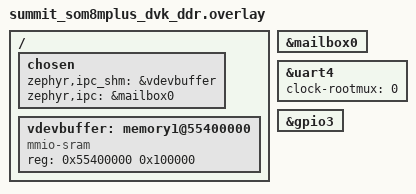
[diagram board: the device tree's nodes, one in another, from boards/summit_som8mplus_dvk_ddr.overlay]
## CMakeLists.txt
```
#
# Copyright (c) 2022 Laird Connectivity
#
# SPDX-License-Identifier: Apache-2.0
#

cmake_minimum_required(VERSION 3.20.0)

# Prepend the additional boards directory but still allow the original Zephyr
# boards directory to be used with lower priority
list(PREPEND BOARD_ROOT ${CMAKE_CURRENT_LIST_DIR}/../../)

set(rpmsg_lite_dir ${CMAKE_CURRENT_SOURCE_DIR}/../../modules/rpmsg_lite)

find_package(Zephyr REQUIRED HINTS $ENV{ZEPHYR_BASE})
project("RPMsg-Lite String Echo Example")

target_sources(app PRIVATE
	${rpmsg_lite_dir}/lib/common/llist.c
	${rpmsg_lite_dir}/lib/rpmsg_lite/rpmsg_lite.c
	${rpmsg_lite_dir}/lib/rpmsg_lite/rpmsg_ns.c
	${rpmsg_lite_dir}/lib/rpmsg_lite/rpmsg_queue.c
	${rpmsg_lite_dir}/lib/virtio/virtqueue.c
	${CMAKE_SOURCE_DIR}/src/main.c
	${CMAKE_SOURCE_DIR}/src/rsc_table.c
	${CMAKE_SOURCE_DIR}/src/rpmsg_env_zephyr.c
	${CMAKE_SOURCE_DIR}/src/rpmsg_platform.c
)

include_directories(
	${rpmsg_lite_dir}/lib/include
	${rpmsg_lite_dir}/lib/include/environment/zephyr
	${rpmsg_lite_dir}/lib/include/platform/imx8mp_m7
	${CMAKE_SOURCE_DIR}/include
)
```

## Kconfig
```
#
# Copyright (c) 2022 Laird Connectivity
#
# SPDX-License-Identifier: Apache-2.0
#

menu "RPMsg-Lite String Echo Example"

config RPMSG_LITE_RESOURCE_TABLE
	bool "coprocessor resource table"
	help
	  Add the resource table in the generated binary. This table is
	  compatible with linux remote proc framework and RPMsg-Lite library.

config RPMSG_LITE_IPC_DEV_NAME
	string "RPMsg-Lite IPC device name"
	default "MAILBOX_0"

config RPMSG_LITE_APP_STACKSIZE
	int "Application thread stack size"
	default 4096

endmenu

module = MAIN
module-str = MAIN
source "subsys/logging/Kconfig.template.log_config"

source "Kconfig.zephyr"
```

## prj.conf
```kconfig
CONFIG_RPMSG_LITE_RESOURCE_TABLE=y
CONFIG_IPM=y
CONFIG_HEAP_MEM_POOL_SIZE=4096
CONFIG_IPM_IMX_REV2=y
CONFIG_IPM_IMX_MAX_DATA_SIZE_4=y
CONFIG_HAVE_CUSTOM_LINKER_SCRIPT=y
CONFIG_CUSTOM_LINKER_SCRIPT="linker.ld"
CONFIG_LOG=y
CONFIG_MAIN_LOG_LEVEL_INF=y
```

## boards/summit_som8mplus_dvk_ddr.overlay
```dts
/*
 * Copyright (c) 2022, Laird Connectivity
 *
 * SPDX-License-Identifier: Apache-2.0
 */

/ {
	chosen {
		/*
		 * shared memory reserved for the inter-processor communication
		 */
		zephyr,ipc_shm = &vdevbuffer;
		zephyr,ipc = &mailbox0;
	};

	vdevbuffer: memory1@55400000 {
		compatible = "mmio-sram";
		reg = <0x55400000 0x100000>;
	};
};

&mailbox0 {
	status = "okay";
};

&uart4 {
	clock-rootmux = <0>;
};

&gpio3 {
	status = "okay";
};
```

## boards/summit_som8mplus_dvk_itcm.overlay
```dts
/*
 * Copyright (c) 2022, Laird Connectivity
 *
 * SPDX-License-Identifier: Apache-2.0
 */

/ {
	chosen {
		/*
		 * shared memory reserved for the inter-processor communication
		 */
		zephyr,ipc_shm = &vdevbuffer;
		zephyr,ipc = &mub;
	};

	vdevbuffer: memory1@55400000 {
		compatible = "mmio-sram";
		reg = <0x55400000 0x100000>;
	};
};

&mub {
	status ="okay";
};
```

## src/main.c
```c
/*
 * Copyright (c) 2022 Laird Connectivity
 *
 * SPDX-License-Identifier: Apache-2.0
 */

#include <zephyr.h>
#include <stdint.h>
#include <string.h>

#include "rpmsg_lite.h"
#include "rpmsg_queue.h"
#include "rpmsg_ns.h"
#include "rsc_table.h"
#include "rpmsg_lite_str_echo.h"

#include <logging/log.h>

#include "fsl_rdc.h"

#define M7_DOMAIN_ID (1U)
#define A53_DOMAIN_ID (0U)

LOG_MODULE_REGISTER(main, LOG_LEVEL_INF);

/* Globals */
/* Each RPMSG buffer can carry less than 512 payload */
static char app_buf[512];
static struct k_thread app_thread;
K_THREAD_STACK_DEFINE(app_stack, CONFIG_RPMSG_LITE_APP_STACKSIZE);

void rdc_configure_peripheral_access(void)
{
	rdc_domain_assignment_t assignment = { 0 };
	rdc_periph_access_config_t periph_config;

	assignment.domainId = M7_DOMAIN_ID;

	/* Only configure the RDC if the RDC peripheral write access is allowed. */
	if ((0x1U & RDC_GetPeriphAccessPolicy(RDC, kRDC_Periph_RDC, assignment.domainId)) != 0U) {
		RDC_GetDefaultPeriphAccessConfig(&periph_config);

		/* Give the A53 domain (domain0) access to the I2C3 and SAI3 peripherals. */
		periph_config.policy = RDC_ACCESS_POLICY(A53_DOMAIN_ID, kRDC_ReadWrite);
		periph_config.periph = kRDC_Periph_I2C3;
		RDC_SetPeriphAccessConfig(RDC, &periph_config);
		periph_config.periph = kRDC_Periph_SAI3;
		RDC_SetPeriphAccessConfig(RDC, &periph_config);
	}
}

void app_task(void *p1, void *p2, void *p3)
{
	volatile uint32_t remote_addr;
	struct rpmsg_lite_endpoint *volatile my_ept;
	volatile rpmsg_queue_handle my_queue;
	struct rpmsg_lite_instance *volatile my_rpmsg;
	void *rx_buf;
	uint32_t len;
	int32_t result;
	void *tx_buf;
	uint32_t size;

	ARG_UNUSED(p1);
	ARG_UNUSED(p2);
	ARG_UNUSED(p3);

	copy_resource_table();

	/* Print the initial banner */
	LOG_INF("RPMSG String Echo Zephyr RTOS API Demo");

	my_rpmsg = rpmsg_lite_remote_init((void *)RPMSG_LITE_SHMEM_BASE, RPMSG_LITE_LINK_ID,
					  RL_NO_FLAGS);
	__ASSERT(my_rpmsg != RL_NULL, "Unable to init rpmsg lite");

	while (0 == rpmsg_lite_is_link_up(my_rpmsg))
		;

	my_queue = rpmsg_queue_create(my_rpmsg);
	my_ept = rpmsg_lite_create_ept(my_rpmsg, LOCAL_EPT_ADDR, rpmsg_queue_rx_cb, my_queue);
	(void)rpmsg_ns_announce(my_rpmsg, my_ept, RPMSG_LITE_NS_ANNOUNCE_STRING, RL_NS_CREATE);

	LOG_INF("Nameservice sent, ready for incoming messages...");

	for (;;) {
		/* Get RPMsg rx buffer with message */
		result = rpmsg_queue_recv_nocopy(my_rpmsg, my_queue, (uint32_t *)&remote_addr,
						 (char **)&rx_buf, &len, RL_BLOCK);
		if (result != 0) {
			__ASSERT(false, "Failed to queue the message");
		}

		/* Copy string from RPMsg rx buffer */
		__ASSERT(len < sizeof(app_buf), "rx message is too big");
		memcpy(app_buf, rx_buf, len);
		/* End string by '\0' */
		app_buf[len] = 0;

		if ((len == 2) && (app_buf[0] == 0xd) && (app_buf[1] == 0xa)) {
			LOG_INF("Get New Line From Master Side");
		} else {
			LOG_INF("Get Message From Master Side : \"%s\" [len : %d]", log_strdup(app_buf), len);
		}

		/* Get tx buffer from RPMsg */
		tx_buf = rpmsg_lite_alloc_tx_buffer(my_rpmsg, &size, RL_BLOCK);
		__ASSERT(tx_buf, "Failed to read tx buffer");
		/* Copy string to RPMsg tx buffer */
		memcpy(tx_buf, app_buf, len);
		/* Echo back received message with nocopy send */
		result = rpmsg_lite_send_nocopy(my_rpmsg, my_ept, remote_addr, tx_buf, len);
		if (result != 0) {
			__ASSERT(false, "Failed to send message");
		}
		/* Release held RPMsg rx buffer */
		result = rpmsg_queue_nocopy_free(my_rpmsg, rx_buf);
		if (result != 0) {
			__ASSERT(false, "Failed to free the rx buffer");
		}
	}
}

void main(void)
{
	rdc_configure_peripheral_access();

	k_thread_create(&app_thread, app_stack, CONFIG_RPMSG_LITE_APP_STACKSIZE, app_task, NULL,
			NULL, NULL, -1, K_USER, K_MSEC(0));
}
```

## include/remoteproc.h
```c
/*
 * Copyright (c) 2022 Laird Connectivity
 *
 * SPDX-License-Identifier: Apache-2.0
 */

#ifndef REMOTEPROC_H
#define REMOTEPROC_H

#include <stdint.h>

#if defined __cplusplus
extern "C" {
#endif

#define RSC_NOTIFY_ID_ANY 0xFFFFFFFFUL

#define RPROC_MAX_NAME_LEN 32

/* IAR ARM build tools */
#if defined(__ICCARM__)

#ifndef METAL_PACKED_BEGIN
#define METAL_PACKED_BEGIN __packed
#endif

#ifndef METAL_PACKED_END
#define METAL_PACKED_END
#endif

/* GNUC */
#elif defined(__GNUC__)

#ifndef METAL_PACKED_BEGIN
#define METAL_PACKED_BEGIN
#endif

#ifndef METAL_PACKED_END
#define METAL_PACKED_END __attribute__((__packed__))
#endif

/* ARMCC */
#elif defined(__CC_ARM) || defined(__ARMCC_VERSION)

#ifndef METAL_PACKED_BEGIN
#define METAL_PACKED_BEGIN _Pragma("pack(1U)")
#endif

#ifndef METAL_PACKED_END
#define METAL_PACKED_END _Pragma("pack()")
#endif

#else
/* There is no default definition here to avoid wrong structures packing in case of not supported compiler */
#error Please implement the structure packing macros for your compiler here!
#endif

/**
 * struct resource_table - firmware resource table header
 * @ver: version number
 * @num: number of resource entries
 * @reserved: reserved (must be zero)
 * @offset: array of offsets pointing at the various resource entries
 *
 * A resource table is essentially a list of system resources required
 * by the remote remoteproc. It may also include configuration entries.
 * If needed, the remote remoteproc firmware should contain this table
 * as a dedicated ".resource_table" ELF section.
 *
 * Some resources entries are mere announcements, where the host is informed
 * of specific remoteproc configuration. Other entries require the host to
 * do something (e.g. allocate a system resource). Sometimes a negotiation
 * is expected, where the firmware requests a resource, and once allocated,
 * the host should provide back its details (e.g. address of an allocated
 * memory region).
 *
 * The header of the resource table, as expressed by this structure,
 * contains a version number (should we need to change this format in the
 * future), the number of available resource entries, and their offsets
 * in the table.
 *
 * Immediately following this header are the resource entries themselves,
 * each of which begins with a resource entry header (as described below).
 */
METAL_PACKED_BEGIN
struct resource_table
{
    uint32_t ver;
    uint32_t num;
    uint32_t reserved[2];
    uint32_t offset[0];
} METAL_PACKED_END;

/**
 * struct fw_rsc_hdr - firmware resource entry header
 * @type: resource type
 * @data: resource data
 *
 * Every resource entry begins with a 'struct fw_rsc_hdr' header providing
 * its @type. The content of the entry itself will immediately follow
 * this header, and it should be parsed according to the resource type.
 */
METAL_PACKED_BEGIN
struct fw_rsc_hdr
{
    uint32_t type;
    uint8_t data[0];
} METAL_PACKED_END;

/**
 * enum fw_resource_type - types of resource entries
 *
 * @RSC_CARVEOUT:   request for allocation of a physically contiguous
 *          memory region.
 * @RSC_DEVMEM:     request to iommu_map a memory-based peripheral.
 * @RSC_TRACE:      announces the availability of a trace buffer into which
 *          the remote remoteproc will be writing logs.
 * @RSC_VDEV:       declare support for a virtio device, and serve as its
 *          virtio header.
 * @RSC_VENDOR_START: start of the vendor specific resource types range
 * @RSC_VENDOR_END  : end of the vendor specific resource types range
 * @RSC_LAST:       just keep this one at the end
 *
 * For more details regarding a specific resource type, please see its
 * dedicated structure below.
 *
 * Please note that these values are used as indices to the rproc_handle_rsc
 * lookup table, so please keep them sane. Moreover, @RSC_LAST is used to
 * check the validity of an index before the lookup table is accessed, so
 * please update it as needed.
 */
enum fw_resource_type
{
    RSC_CARVEOUT     = 0,
    RSC_DEVMEM       = 1,
    RSC_TRACE        = 2,
    RSC_VDEV         = 3,
    RSC_LAST         = 4,
    RSC_VENDOR_START = 128,
    RSC_VENDOR_END   = 512,
};

#define FW_RSC_U64_ADDR_ANY 0xFFFFFFFFFFFFFFFFUL
#define FW_RSC_U32_ADDR_ANY 0xFFFFFFFFUL

/**
 * struct fw_rsc_carveout - physically contiguous memory request
 * @da: device address
 * @pa: physical address
 * @len: length (in bytes)
 * @flags: iommu protection flags
 * @reserved: reserved (must be zero)
 * @name: human-readable name of the requested memory region
 *
 * This resource entry requests the host to allocate a physically contiguous
 * memory region.
 *
 * These request entries should precede other firmware resource entries,
 * as other entries might request placing other data objects inside
 * these memory regions (e.g. data/code segments, trace resource entries, ...).
 *
 * Allocating memory this way helps utilizing the reserved physical memory
 * (e.g. CMA) more efficiently, and also minimizes the number of TLB entries
 * needed to map it (in case @rproc is using an IOMMU). Reducing the TLB
 * pressure is important; it may have a substantial impact on performance.
 *
 * If the firmware is compiled with static addresses, then @da should specify
 * the expected device address of this memory region. If @da is set to
 * FW_RSC_ADDR_ANY, then the host will dynamically allocate it, and then
 * overwrite @da with the dynamically allocated address.
 *
 * We will always use @da to negotiate the device addresses, even if it
 * isn't using an iommu. In that case, though, it will obviously contain
 * physical addresses.
 *
 * Some remote remoteprocs needs to know the allocated physical address
 * even if they do use an iommu. This is needed, e.g., if they control
 * hardware accelerators which access the physical memory directly (this
 * is the case with OMAP4 for instance). In that case, the host will
 * overwrite @pa with the dynamically allocated physical address.
 * Generally we don't want to expose physical addresses if we don't have to
 * (remote remoteprocs are generally _not_ trusted), so we might want to
 * change this to happen _only_ when explicitly required by the hardware.
 *
 * @flags is used to provide IOMMU protection flags, and @name should
 * (optionally) contain a human readable name of this carveout region
 * (mainly for debugging purposes).
 */
METAL_PACKED_BEGIN
struct fw_rsc_carveout
{
    uint32_t type;
    uint32_t da;
    uint32_t pa;
    uint32_t len;
    uint32_t flags;
    uint32_t reserved;
    uint8_t name[RPROC_MAX_NAME_LEN];
} METAL_PACKED_END;

/**
 * struct fw_rsc_devmem - iommu mapping request
 * @da: device address
 * @pa: physical address
 * @len: length (in bytes)
 * @flags: iommu protection flags
 * @reserved: reserved (must be zero)
 * @name: human-readable name of the requested region to be mapped
 *
 * This resource entry requests the host to iommu map a physically contiguous
 * memory region. This is needed in case the remote remoteproc requires
 * access to certain memory-based peripherals; _never_ use it to access
 * regular memory.
 *
 * This is obviously only needed if the remote remoteproc is accessing memory
 * via an iommu.
 *
 * @da should specify the required device address, @pa should specify
 * the physical address we want to map, @len should specify the size of
 * the mapping and @flags is the IOMMU protection flags. As always, @name may
 * (optionally) contain a human readable name of this mapping (mainly for
 * debugging purposes).
 *
 * Note: at this point we just "trust" those devmem entries to contain valid
 * physical addresses, but this isn't safe and will be changed: eventually we
 * want remoteproc implementations to provide us ranges of physical addresses
 * the firmware is allowed to request, and not allow firmwares to request
 * access to physical addresses that are outside those ranges.
 */
METAL_PACKED_BEGIN
struct fw_rsc_devmem
{
    uint32_t type;
    uint32_t da;
    uint32_t pa;
    uint32_t len;
    uint32_t flags;
    uint32_t reserved;
    uint8_t name[RPROC_MAX_NAME_LEN];
} METAL_PACKED_END;

/**
 * struct fw_rsc_trace - trace buffer declaration
 * @da: device address
 * @len: length (in bytes)
 * @reserved: reserved (must be zero)
 * @name: human-readable name of the trace buffer
 *
 * This resource entry provides the host information about a trace buffer
 * into which the remote remoteproc will write log messages.
 *
 * @da specifies the device address of the buffer, @len specifies
 * its size, and @name may contain a human readable name of the trace buffer.
 *
 * After booting the remote remoteproc, the trace buffers are exposed to the
 * user via debugfs entries (called trace0, trace1, etc..).
 */
METAL_PACKED_BEGIN
struct fw_rsc_trace
{
    uint32_t type;
    uint32_t da;
    uint32_t len;
    uint32_t reserved;
    uint8_t name[RPROC_MAX_NAME_LEN];
} METAL_PACKED_END;

/**
 * struct fw_rsc_vdev_vring - vring descriptor entry
 * @da: device address
 * @align: the alignment between the consumer and producer parts of the vring
 * @num: num of buffers supported by this vring (must be power of two)
 * @notifyid is a unique rproc-wide notify index for this vring. This notify
 * index is used when kicking a remote remoteproc, to let it know that this
 * vring is triggered.
 * @reserved: reserved (must be zero)
 *
 * This descriptor is not a resource entry by itself; it is part of the
 * vdev resource type (see below).
 *
 * Note that @da should either contain the device address where
 * the remote remoteproc is expecting the vring, or indicate that
 * dynamically allocation of the vring's device address is supported.
 */
METAL_PACKED_BEGIN
struct fw_rsc_vdev_vring
{
    uint32_t da;
    uint32_t align;
    uint32_t num;
    uint32_t notifyid;
    uint32_t reserved;
} METAL_PACKED_END;

/**
 * struct fw_rsc_vdev - virtio device header
 * @id: virtio device id (as in virtio_ids.h)
 * @notifyid is a unique rproc-wide notify index for this vdev. This notify
 * index is used when kicking a remote remoteproc, to let it know that the
 * status/features of this vdev have changes.
 * @dfeatures specifies the virtio device features supported by the firmware
 * @gfeatures is a place holder used by the host to write back the
 * negotiated features that are supported by both sides.
 * @config_len is the size of the virtio config space of this vdev. The config
 * space lies in the resource table immediate after this vdev header.
 * @status is a place holder where the host will indicate its virtio progress.
 * @num_of_vrings indicates how many vrings are described in this vdev header
 * @reserved: reserved (must be zero)
 * @vring is an array of @num_of_vrings entries of 'struct fw_rsc_vdev_vring'.
 *
 * This resource is a virtio device header: it provides information about
 * the vdev, and is then used by the host and its peer remote remoteprocs
 * to negotiate and share certain virtio properties.
 *
 * By providing this resource entry, the firmware essentially asks remoteproc
 * to statically allocate a vdev upon registration of the rproc (dynamic vdev
 * allocation is not yet supported).
 *
 * Note: unlike virtualization systems, the term 'host' here means
 * the Linux side which is running remoteproc to control the remote
 * remoteprocs. We use the name 'gfeatures' to comply with virtio's terms,
 * though there isn't really any virtualized guest OS here: it's the host
 * which is responsible for negotiating the final features.
 * Yeah, it's a bit confusing.
 *
 * Note: immediately following this structure is the virtio config space for
 * this vdev (which is specific to the vdev; for more info, read the virtio
 * spec). the size of the config space is specified by @config_len.
 */
METAL_PACKED_BEGIN
struct fw_rsc_vdev
{
    uint32_t type;
    uint32_t id;
    uint32_t notifyid;
    uint32_t dfeatures;
    uint32_t gfeatures;
    uint32_t config_len;
    uint8_t status;
    uint8_t num_of_vrings;
    uint8_t reserved[2];
    struct fw_rsc_vdev_vring vring[0];
} METAL_PACKED_END;

/**
 * struct fw_rsc_vendor - remote processor vendor specific resource
 * @len: length of the resource
 *
 * This resource entry tells the host the vendor specific resource
 * required by the remote.
 *
 * These request entries should precede other shared resource entries
 * such as vdevs, vrings.
 */
METAL_PACKED_BEGIN
struct fw_rsc_vendor
{
    uint32_t type;
    uint32_t len;
} METAL_PACKED_END;

#if defined __cplusplus
}
#endif

#endif /* REMOTEPROC_H_ */
```

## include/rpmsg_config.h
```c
/*
 * Copyright (c) 2022 Laird Connectivity
 *
 * SPDX-License-Identifier: Apache-2.0
 */

#ifndef RPMSG_CONFIG_H_
#define RPMSG_CONFIG_H_

/*!
 * @addtogroup config
 * @{
 * @file
 */

//! @name Configuration options
//@{

//! @def RL_MS_PER_INTERVAL
//!
//! Delay in milliseconds used in non-blocking API functions for polling.
//! The default value is 1.
#define RL_MS_PER_INTERVAL (1)

//! @def RL_BUFFER_PAYLOAD_SIZE
//!
//! Size of the buffer payload, it must be equal to (240, 496, 1008, ...)
//! [2^n - 16]. Ensure the same value is defined on both sides of rpmsg
//! communication. The default value is 496U.
#define RL_BUFFER_PAYLOAD_SIZE (496U)

//! @def RL_BUFFER_COUNT
//!
//! Number of the buffers, it must be power of two (2, 4, ...).
//! The default value is 2U.
//! Note this value defines the buffer count for one direction of the rpmsg
//! communication only, i.e. if the default value of 2 is used
//! in rpmsg_config.h files for the master and the remote side, 4 buffers
//! in total are created in the shared memory.
#define RL_BUFFER_COUNT (256U)

//! @def RL_API_HAS_ZEROCOPY
//!
//! Zero-copy API functions enabled/disabled.
//! The default value is 1 (enabled).
#define RL_API_HAS_ZEROCOPY (1)

//! @def RL_USE_STATIC_API
//!
//! Static API functions (no dynamic allocation) enabled/disabled.
//! The default value is 0 (static API disabled).
#define RL_USE_STATIC_API (0)

//! @def RL_CLEAR_USED_BUFFERS
//!
//! Clearing used buffers before returning back to the pool of free buffers
//! enabled/disabled.
//! The default value is 0 (disabled).
#define RL_CLEAR_USED_BUFFERS (0)

//! @def RL_USE_MCMGR_IPC_ISR_HANDLER
//!
//! When enabled IPC interrupts are managed by the Multicore Manager (IPC
//! interrupts router), when disabled RPMsg-Lite manages IPC interrupts
//! by itself.
//! The default value is 0 (no MCMGR IPC ISR handler used).
#define RL_USE_MCMGR_IPC_ISR_HANDLER (0)

//! @def RL_USE_ENVIRONMENT_CONTEXT
//!
//! When enabled the environment layer uses its own context.
//! Added for QNX port mainly, but can be used if required.
//! The default value is 0 (no context, saves some RAM).
#define RL_USE_ENVIRONMENT_CONTEXT (0)

//! @def RL_DEBUG_CHECK_BUFFERS
//!
//! Do not use in RPMsg-Lite to Linux configuration
#define RL_DEBUG_CHECK_BUFFERS (0)
//@}

typedef struct {
	uint32_t src;
	void *data;
	uint32_t len;
} rpmsg_queue_rx_cb_data_t;

#endif /* RPMSG_CONFIG_H_ */
```

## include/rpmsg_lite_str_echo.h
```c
/*
 * Copyright (c) 2022 Laird Connectivity
 *
 * SPDX-License-Identifier: Apache-2.0
 */

#ifndef RPMSG_LITE_STR_ECHO_H
#define RPMSG_LITE_STR_ECHO_H

/*******************************************************************************
 * Definitions
 ******************************************************************************/

/* Shared memory base for RPMsg communication. */
#define VDEV0_VRING_BASE (0x55000000U)
#define RESOURCE_TABLE_OFFSET (0xFF000)

#define RPMSG_LITE_SHMEM_BASE (VDEV0_VRING_BASE)
#define RPMSG_LITE_LINK_ID (RL_PLATFORM_IMX8MP_M7_USER_LINK_ID)
#define RPMSG_LITE_NS_ANNOUNCE_STRING "rpmsg-virtual-tty-channel-1"
#define APP_TASK_STACK_SIZE (256)
#ifndef LOCAL_EPT_ADDR
#define LOCAL_EPT_ADDR (30)
#endif

#endif // RPMSG_LITE_STR_ECHO_H
```

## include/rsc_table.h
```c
/*
 * Copyright (c) 2022 Laird Connectivity
 *
 * SPDX-License-Identifier: Apache-2.0
 */

/* This file populates resource table for BM remote
 * for use by the Linux Master */

#ifndef RSC_TABLE_H_
#define RSC_TABLE_H_

#include "rpmsg_lite_str_echo.h"
#include <stddef.h>
#include <remoteproc.h>

#if defined __cplusplus
extern "C" {
#endif

#define NO_RESOURCE_ENTRIES (1)
#define RSC_VDEV_FEATURE_NS (1) /* Support name service announcement */

/* Resource table for the given remote */
METAL_PACKED_BEGIN
struct remote_resource_table {
	uint32_t version;
	uint32_t num;
	uint32_t reserved[2];
	uint32_t offset[NO_RESOURCE_ENTRIES];

	/* rpmsg vdev entry for user app communication */
	struct fw_rsc_vdev user_vdev;
	struct fw_rsc_vdev_vring user_vring0;
	struct fw_rsc_vdev_vring user_vring1;
} METAL_PACKED_END;

/*
 * Copy resource table to shared memory base for early M4 boot case.
 * In M4 early boot case, Linux kernel need to get resource table before file system gets loaded.
 */
void copy_resource_table(void);

#if defined __cplusplus
}
#endif

#endif /* RSC_TABLE_H_ */
```

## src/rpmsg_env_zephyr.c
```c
/*
 * Copyright (c) 2014, Mentor Graphics Corporation
 * Copyright (c) 2015 Xilinx, Inc.
 * Copyright (c) 2016 Freescale Semiconductor, Inc.
 * Copyright 2016-2021 NXP
 * Copyright (c) 2022 Laird Connectivity
 * All rights reserved.
 *
 * Redistribution and use in source and binary forms, with or without
 * modification, are permitted provided that the following conditions are met:
 *
 * 1. Redistributions of source code must retain the above copyright notice,
 *    this list of conditions and the following disclaimer.
 * 2. Redistributions in binary form must reproduce the above copyright notice,
 *    this list of conditions and the following disclaimer in the documentation
 *    and/or other materials provided with the distribution.
 * 3. Neither the name of the copyright holder nor the names of its
 *    contributors may be used to endorse or promote products derived from this
 *    software without specific prior written permission.
 *
 * THIS SOFTWARE IS PROVIDED BY THE COPYRIGHT HOLDERS AND CONTRIBUTORS "AS IS"
 * AND ANY EXPRESS OR IMPLIED WARRANTIES, INCLUDING, BUT NOT LIMITED TO, THE
 * IMPLIED WARRANTIES OF MERCHANTABILITY AND FITNESS FOR A PARTICULAR PURPOSE
 * ARE DISCLAIMED. IN NO EVENT SHALL THE COPYRIGHT HOLDER OR CONTRIBUTORS BE
 * LIABLE FOR ANY DIRECT, INDIRECT, INCIDENTAL, SPECIAL, EXEMPLARY, OR
 * CONSEQUENTIAL DAMAGES (INCLUDING, BUT NOT LIMITED TO, PROCUREMENT OF
 * SUBSTITUTE GOODS OR SERVICES; LOSS OF USE, DATA, OR PROFITS; OR BUSINESS
 * INTERRUPTION) HOWEVER CAUSED AND ON ANY THEORY OF LIABILITY, WHETHER IN
 * CONTRACT, STRICT LIABILITY, OR TORT (INCLUDING NEGLIGENCE OR OTHERWISE)
 * ARISING IN ANY WAY OUT OF THE USE OF THIS SOFTWARE, EVEN IF ADVISED OF THE
 * POSSIBILITY OF SUCH DAMAGE.
 */

/**************************************************************************
 * FILE NAME
 *
 *       rpmsg_env_zephyr.c
 *
 *
 * DESCRIPTION
 *
 *       This file is Zephyr RTOS Implementation of env layer for OpenAMP.
 *
 *
 **************************************************************************/

#include "rpmsg_env.h"
#include <zephyr.h>
#include "rpmsg_platform.h"
#include "virtqueue.h"
#include "rpmsg_compiler.h"

#include <stdlib.h>
#include <string.h>

#if defined(RL_USE_ENVIRONMENT_CONTEXT) && (RL_USE_ENVIRONMENT_CONTEXT == 1)
#error "This RPMsg-Lite port requires RL_USE_ENVIRONMENT_CONTEXT set to 0"
#endif

/* RL_ENV_MAX_MUTEX_COUNT is an arbitrary count greater than 'count'
   if the inital count is 1, this function behaves as a mutex
   if it is greater than 1, it acts as a "resource allocator" with
   the maximum of 'count' resources available.
   Currently, only the first use-case is applicable/applied in RPMsg-Lite.
 */
#define RL_ENV_MAX_MUTEX_COUNT (10)

static int32_t env_init_counter = 0;
static struct k_sem env_sema = { 0 };

/* Max supported ISR counts */
#define ISR_COUNT (32U)
/*!
 * Structure to keep track of registered ISR's.
 */
struct isr_info {
	void *data;
};
static struct isr_info isr_table[ISR_COUNT];

/*!
 * env_in_isr
 *
 * @returns - true, if currently in ISR
 *
 */
static int32_t env_in_isr(void)
{
	return platform_in_isr();
}

/*!
 * env_init
 *
 * Initializes OS/BM environment.
 *
 */
int32_t env_init(void)
{
	int32_t retval;

	/* stop scheduler */
	k_sched_lock();
	/* verify 'env_init_counter' */
	RL_ASSERT(env_init_counter >= 0);
	if (env_init_counter < 0) {
		/* re-enable scheduler */
		k_sched_unlock();
		return -1;
	}
	env_init_counter++;
	/* multiple call of 'env_init' - return ok */
	if (env_init_counter == 1) {
		/* first call */
		k_sem_init(&env_sema, 0, 1);
		(void)memset(isr_table, 0, sizeof(isr_table));
		k_sched_unlock();
		retval = platform_init();
		k_sem_give(&env_sema);

		return retval;
	} else {
		k_sched_unlock();
		/*
		 * Get the semaphore and then return it, this allows for platform_init() to block if
		 * needed and other tasks to wait for the blocking to be done. This is in ENV layer
		 * as this is ENV specific.
		 */
		k_sem_take(&env_sema, K_FOREVER);
		k_sem_give(&env_sema);
		return 0;
	}
}

/*!
 * env_deinit
 *
 * Uninitializes OS/BM environment.
 *
 * @returns - execution status
 */
int32_t env_deinit(void)
{
	int32_t retval;

	/* stop scheduler */
	k_sched_lock();
	/* verify 'env_init_counter' */
	RL_ASSERT(env_init_counter > 0);
	if (env_init_counter <= 0) {
		/* re-enable scheduler */
		k_sched_unlock();
		return -1;
	}

	/* counter on zero - call platform deinit */
	env_init_counter--;
	/* multiple call of 'env_deinit' - return ok */
	if (env_init_counter <= 0) {
		/* last call */
		(void)memset(isr_table, 0, sizeof(isr_table));
		retval = platform_deinit();
		k_sem_reset(&env_sema);
		k_sched_unlock();

		return retval;
	} else {
		k_sched_unlock();
		return 0;
	}
}

/*!
 * env_allocate_memory - implementation
 *
 * @param size
 */
void *env_allocate_memory(uint32_t size)
{
	return (k_malloc(size));
}

/*!
 * env_free_memory - implementation
 *
 * @param ptr
 */
void env_free_memory(void *ptr)
{
	if (ptr != ((void *)0)) {
		k_free(ptr);
	}
}

/*!
 *
 * env_memset - implementation
 *
 * @param ptr
 * @param value
 * @param size
 */
void env_memset(void *ptr, int32_t value, uint32_t size)
{
	(void)memset(ptr, value, size);
}

/*!
 *
 * env_memcpy - implementation
 *
 * @param dst
 * @param src
 * @param len
 */
void env_memcpy(void *dst, void const *src, uint32_t len)
{
	(void)memcpy(dst, src, len);
}

/*!
 *
 * env_strcmp - implementation
 *
 * @param dst
 * @param src
 */

int32_t env_strcmp(const char *dst, const char *src)
{
	return (strcmp(dst, src));
}

/*!
 *
 * env_strncpy - implementation
 *
 * @param dst
 * @param src
 * @param len
 */
void env_strncpy(char *dst, const char *src, uint32_t len)
{
	(void)strncpy(dst, src, len);
}

/*!
 *
 * env_strncmp - implementation
 *
 * @param dst
 * @param src
 * @param len
 */
int32_t env_strncmp(char *dst, const char *src, uint32_t len)
{
	return (strncmp(dst, src, len));
}

/*!
 *
 * env_mb - implementation
 *
 */
void env_mb(void)
{
	MEM_BARRIER();
}

/*!
 * env_rmb - implementation
 */
void env_rmb(void)
{
	MEM_BARRIER();
}

/*!
 * env_wmb - implementation
 */
void env_wmb(void)
{
	MEM_BARRIER();
}

/*!
 * env_map_vatopa - implementation
 *
 * @param address
 */
uint32_t env_map_vatopa(void *address)
{
	return platform_vatopa(address);
}

/*!
 * env_map_patova - implementation
 *
 * @param address
 */
void *env_map_patova(uint32_t address)
{
	return platform_patova(address);
}

/*!
 * env_create_mutex
 *
 * Creates a mutex with the given initial count.
 *
 */
#if defined(RL_USE_STATIC_API) && (RL_USE_STATIC_API == 1)
int32_t env_create_mutex(void **lock, int32_t count, void *context)
#else
int32_t env_create_mutex(void **lock, int32_t count)
#endif
{
	struct k_sem *semaphore_ptr;

	if (count > RL_ENV_MAX_MUTEX_COUNT) {
		return -1;
	}

#if defined(RL_USE_STATIC_API) && (RL_USE_STATIC_API == 1)
	semaphore_ptr = (struct k_sem *)context;
#else
	semaphore_ptr = (struct k_sem *)env_allocate_memory(sizeof(struct k_sem));
#endif
	if (semaphore_ptr == ((void *)0)) {
		return -1;
	}

	k_sem_init(semaphore_ptr, count, RL_ENV_MAX_MUTEX_COUNT);
	/*
	 * Becasue k_sem_init() does not return any status, we do not know if all is OK or not. If
	 * something would not be OK dynamically allocated memory has to be freed here.
	 */

	*lock = (void *)semaphore_ptr;
	return 0;
}

/*!
 * env_delete_mutex
 *
 * Deletes the given lock
 *
 */
void env_delete_mutex(void *lock)
{
	k_sem_reset(lock);
#if !(defined(RL_USE_STATIC_API) && (RL_USE_STATIC_API == 1))
	env_free_memory(lock);
#endif
}

/*!
 * env_lock_mutex
 *
 * Tries to acquire the lock, if lock is not available then call to this function will suspend.
 */
void env_lock_mutex(void *lock)
{
	if (env_in_isr() == 0) {
		k_sem_take((struct k_sem *)lock, K_FOREVER);
	}
}

/*!
 * env_unlock_mutex
 *
 * Releases the given lock.
 */
void env_unlock_mutex(void *lock)
{
	if (env_in_isr() == 0) {
		k_sem_give((struct k_sem *)lock);
	}
}

/*!
 * env_create_sync_lock
 *
 * Creates a synchronization lock primitive. It is used when signal has to be sent from the
 * interrupt context to main thread context.
 */
#if defined(RL_USE_STATIC_API) && (RL_USE_STATIC_API == 1)
int32_t env_create_sync_lock(void **lock, int32_t state, void *context)
{
	/* state=1 .. initially free */
	return env_create_mutex(lock, state, context);
}
#else
int32_t env_create_sync_lock(void **lock, int32_t state)
{
	/* state=1 .. initially free */
	return env_create_mutex(lock, state);
}
#endif

/*!
 * env_delete_sync_lock
 *
 * Deletes the given lock
 *
 */
void env_delete_sync_lock(void *lock)
{
	if (lock != ((void *)0)) {
		env_delete_mutex(lock);
	}
}

/*!
 * env_acquire_sync_lock
 *
 * Tries to acquire the lock, if lock is not available then call to this function waits for lock to
 * become available.
 */
void env_acquire_sync_lock(void *lock)
{
	if (lock != ((void *)0)) {
		env_lock_mutex(lock);
	}
}

/*!
 * env_release_sync_lock
 *
 * Releases the given lock.
 */
void env_release_sync_lock(void *lock)
{
	if (lock != ((void *)0)) {
		env_unlock_mutex(lock);
	}
}

/*!
 * env_sleep_msec
 *
 * Suspends the calling thread for given time , in msecs.
 */
void env_sleep_msec(uint32_t num_msec)
{
	k_msleep(num_msec);
}

/*!
 * env_register_isr
 *
 * Registers interrupt handler data for the given interrupt vector.
 *
 * @param vector_id - virtual interrupt vector number
 * @param data      - interrupt handler data (virtqueue)
 */
void env_register_isr(uint32_t vector_id, void *data)
{
	RL_ASSERT(vector_id < ISR_COUNT);
	if (vector_id < ISR_COUNT) {
		isr_table[vector_id].data = data;
	}
}

/*!
 * env_unregister_isr
 *
 * Unregisters interrupt handler data for the given interrupt vector.
 *
 * @param vector_id - virtual interrupt vector number
 */
void env_unregister_isr(uint32_t vector_id)
{
	RL_ASSERT(vector_id < ISR_COUNT);
	if (vector_id < ISR_COUNT) {
		isr_table[vector_id].data = ((void *)0);
	}
}

/*!
 * env_enable_interrupt
 *
 * Enables the given interrupt
 *
 * @param vector_id   - interrupt vector number
 */

void env_enable_interrupt(uint32_t vector_id)
{
	(void)platform_interrupt_enable(vector_id);
}

/*!
 * env_disable_interrupt
 *
 * Disables the given interrupt
 *
 * @param vector_id   - interrupt vector number
 */

void env_disable_interrupt(uint32_t vector_id)
{
	(void)platform_interrupt_disable(vector_id);
}

/*!
 * env_map_memory
 *
 * Enables memory mapping for given memory region.
 *
 * @param pa   - physical address of memory
 * @param va   - logical address of memory
 * @param size - memory size
 * param flags - flags for cache/uncached  and access type
 */

void env_map_memory(uint32_t pa, uint32_t va, uint32_t size, uint32_t flags)
{
	platform_map_mem_region(va, pa, size, flags);
}

/*!
 * env_disable_cache
 *
 * Disables system caches.
 *
 */

void env_disable_cache(void)
{
	platform_cache_all_flush_invalidate();
	platform_cache_disable();
}

/*========================================================= */
/* Util data / functions  */

void env_isr(uint32_t vector)
{
	struct isr_info *info;
	RL_ASSERT(vector < ISR_COUNT);
	if (vector < ISR_COUNT) {
		info = &isr_table[vector];
		virtqueue_notification((struct virtqueue *)info->data);
	}
}

/*
 * env_create_queue
 *
 * Creates a message queue.
 *
 * @param queue -  pointer to created queue
 * @param length -  maximum number of elements in the queue
 * @param element_size - queue element size in bytes
 * @param queue_static_storage - pointer to queue static storage buffer
 * @param queue_static_context - pointer to queue static context
 *
 * @return - status of function execution
 */
#if defined(RL_USE_STATIC_API) && (RL_USE_STATIC_API == 1)
int32_t env_create_queue(void **queue, int32_t length, int32_t element_size,
			 uint8_t *queue_static_storage,
			 rpmsg_static_queue_ctxt *queue_static_context)
#else
int32_t env_create_queue(void **queue, int32_t length, int32_t element_size)
#endif
{
	struct k_msgq *queue_ptr = ((void *)0);
	char *msgq_buffer_ptr = ((void *)0);

#if defined(RL_USE_STATIC_API) && (RL_USE_STATIC_API == 1)
	queue_ptr = (struct k_msgq *)queue_static_context;
	msgq_buffer_ptr = (char *)queue_static_storage;
#else
	queue_ptr = (struct k_msgq *)env_allocate_memory(sizeof(struct k_msgq));
	msgq_buffer_ptr = (char *)env_allocate_memory(length * element_size);
#endif
	if ((queue_ptr == ((void *)0)) || (msgq_buffer_ptr == ((void *)0))) {
		return -1;
	}
	k_msgq_init(queue_ptr, msgq_buffer_ptr, element_size, length);
	/*
	 * Becasue k_msgq_init() does not return any status, we do not know if all is OK or not. If
	 * something would not be OK dynamically allocated memory has to be freed here.
	 */

	*queue = (void *)queue_ptr;
	return 0;
}

/*!
 * env_delete_queue
 *
 * Deletes the message queue.
 *
 * @param queue - queue to delete
 */

void env_delete_queue(void *queue)
{
	k_msgq_purge((struct k_msgq *)queue);
#if !(defined(RL_USE_STATIC_API) && (RL_USE_STATIC_API == 1))
	env_free_memory(((struct k_msgq *)queue)->buffer_start);
	env_free_memory(queue);
#endif
}

/*!
 * env_put_queue
 *
 * Put an element in a queue.
 *
 * @param queue - queue to put element in
 * @param msg - pointer to the message to be put into the queue
 * @param timeout_ms - timeout in ms
 *
 * @return - status of function execution
 */

int32_t env_put_queue(void *queue, void *msg, uint32_t timeout_ms)
{
	if (env_in_isr() != 0) {
		timeout_ms = 0; /* force timeout == 0 when in ISR */
	}

	if (0 == k_msgq_put((struct k_msgq *)queue, msg, K_MSEC(timeout_ms))) {
		return 1;
	}
	return 0;
}

/*!
 * env_get_queue
 *
 * Get an element out of a queue.
 *
 * @param queue - queue to get element from
 * @param msg - pointer to a memory to save the message
 * @param timeout_ms - timeout in ms
 *
 * @return - status of function execution
 */

int32_t env_get_queue(void *queue, void *msg, uint32_t timeout_ms)
{
	if (env_in_isr() != 0) {
		timeout_ms = 0; /* force timeout == 0 when in ISR */
	}

	if (0 == k_msgq_get((struct k_msgq *)queue, msg, K_MSEC(timeout_ms))) {
		return 1;
	}
	return 0;
}

/*!
 * env_get_current_queue_size
 *
 * Get current queue size.
 *
 * @param queue - queue pointer
 *
 * @return - Number of queued items in the queue
 */

int32_t env_get_current_queue_size(void *queue)
{
	return k_msgq_num_used_get((struct k_msgq *)queue);
}
```

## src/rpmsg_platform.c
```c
/*
 * Copyright 2019-2020 NXP
 * Copyright (c) 2022 Laird Connectivity
 * All rights reserved.
 *
 *
 * SPDX-License-Identifier: BSD-3-Clause
 */

#include <zephyr.h>
#include <stdio.h>
#include <string.h>
#include "rpmsg_platform.h"
#include "rpmsg_env.h"

#include "fsl_device_registers.h"
#include "fsl_mu.h"
#include "irq.h"
#include <drivers/ipm.h>
#include <logging/log.h>
LOG_MODULE_REGISTER(rpmsg_platform, LOG_LEVEL_DBG);

#if defined(RL_USE_ENVIRONMENT_CONTEXT) && (RL_USE_ENVIRONMENT_CONTEXT == 1)
#error "This RPMsg-Lite port requires RL_USE_ENVIRONMENT_CONTEXT set to 0"
#endif

#if !DT_HAS_CHOSEN(zephyr_ipc_shm)
#error "Sample requires definition of shared memory for rpmsg"
#endif

static int32_t isr_counter = 0;
static int32_t disable_counter = 0;
static void *platform_lock;
static const struct device *ipm_handle;

static void platform_global_isr_disable(void)
{
	__asm volatile("cpsid i");
}

static void platform_global_isr_enable(void)
{
	__asm volatile("cpsie i");
}

int32_t platform_init_interrupt(uint32_t vector_id, void *isr_data)
{
	/* Register ISR to environment layer */
	env_register_isr(vector_id, isr_data);

	/* Prepare the MU Hardware, enable channel 1 interrupt */
	env_lock_mutex(platform_lock);

	RL_ASSERT(0 <= isr_counter);
	if (isr_counter == 0) {
		ipm_set_enabled(ipm_handle, 1);
	}
	isr_counter++;

	env_unlock_mutex(platform_lock);

	return 0;
}

int32_t platform_deinit_interrupt(uint32_t vector_id)
{
	/* Prepare the MU Hardware */
	env_lock_mutex(platform_lock);

	RL_ASSERT(0 < isr_counter);
	isr_counter--;
	if (isr_counter == 0) {
		ipm_set_enabled(ipm_handle, 0);
	}

	/* Unregister ISR from environment layer */
	env_unregister_isr(vector_id);

	env_unlock_mutex(platform_lock);

	return 0;
}

void platform_notify(uint32_t vector_id)
{
	/* As Linux suggests, use MU->Data Channel 1 as communication channel */
	uint32_t msg = (uint32_t)(vector_id << 16);
	int ret = 0;

	env_lock_mutex(platform_lock);

	ret = ipm_send(ipm_handle, 0, RPMSG_MU_CHANNEL, &msg, 1);
	if (ret != 0) {
		LOG_WRN("ipm_send failed! ret: %d", ret);
	}

	env_unlock_mutex(platform_lock);
}

/*
 * MU Interrrupt RPMsg handler
 */
void MU1_M7_IRQHandler(const struct device *dev, void *context, uint32_t id, volatile void *data)
{
	uint32_t *data32 = (uint32_t *)data;

	/* Call the environment ISR */
	env_isr(data32[0] >> 16);
}

/**
 * platform_time_delay
 *
 * @param num_msec Delay time in ms.
 */
void platform_time_delay(uint32_t num_msec)
{
	k_sleep(K_MSEC(num_msec));
}

/**
 * platform_in_isr
 *
 * Return whether CPU is processing IRQ
 *
 * @return True for IRQ, false otherwise.
 *
 */
int32_t platform_in_isr(void)
{
	return (((SCB->ICSR & SCB_ICSR_VECTACTIVE_Msk) != 0UL) ? 1 : 0);
}

/**
 * platform_interrupt_enable
 *
 * Enable peripheral-related interrupt
 *
 * @param vector_id Virtual vector ID that needs to be converted to IRQ number
 *
 * @return vector_id Return value is never checked.
 *
 */
int32_t platform_interrupt_enable(uint32_t vector_id)
{
	RL_ASSERT(0 < disable_counter);

	platform_global_isr_disable();
	disable_counter--;

	if (disable_counter == 0) {
		irq_enable(MU1_M7_IRQn);
	}
	platform_global_isr_enable();
	return ((int32_t)vector_id);
}

/**
 * platform_interrupt_disable
 *
 * Disable peripheral-related interrupt.
 *
 * @param vector_id Virtual vector ID that needs to be converted to IRQ number
 *
 * @return vector_id Return value is never checked.
 *
 */
int32_t platform_interrupt_disable(uint32_t vector_id)
{
	RL_ASSERT(0 <= disable_counter);

	platform_global_isr_disable();
	/* virtqueues use the same NVIC vector
	   if counter is set - the interrupts are disabled */
	if (disable_counter == 0) {
		irq_disable(MU1_M7_IRQn);
	}
	disable_counter++;
	platform_global_isr_enable();
	return ((int32_t)vector_id);
}

/**
 * platform_map_mem_region
 *
 * Dummy implementation
 *
 */
void platform_map_mem_region(uint32_t vrt_addr, uint32_t phy_addr, uint32_t size, uint32_t flags)
{
}

/**
 * platform_cache_all_flush_invalidate
 *
 * Dummy implementation
 *
 */
void platform_cache_all_flush_invalidate(void)
{
}

/**
 * platform_cache_disable
 *
 * Dummy implementation
 *
 */
void platform_cache_disable(void)
{
}

/**
 * platform_vatopa
 *
 * Dummy implementation
 *
 */
uint32_t platform_vatopa(void *addr)
{
	return ((uint32_t)(char *)addr);
}

/**
 * platform_patova
 *
 * Dummy implementation
 *
 */
void *platform_patova(uint32_t addr)
{
	return ((void *)(char *)addr);
}

/**
 * platform_init
 *
 * platform/environment init
 */
int32_t platform_init(void)
{
	/* setup IPM */
	ipm_handle = device_get_binding(CONFIG_RPMSG_LITE_IPC_DEV_NAME);
	if (!ipm_handle) {
		LOG_ERR("%s: Failed to find ipm device", __func__);
		return -1;
	}
	if (!device_is_ready(ipm_handle)) {
		while (1) {
		}
	}

	ipm_register_callback(ipm_handle, MU1_M7_IRQHandler, NULL);

	/* Create lock used in multi-instanced RPMsg */
	if (0 != env_create_mutex(&platform_lock, 1)) {
		return -1;
	}

	return 0;
}

/**
 * platform_deinit
 *
 * platform/environment deinit process
 */
int32_t platform_deinit(void)
{
	/* Delete lock used in multi-instanced RPMsg */
	env_delete_mutex(platform_lock);
	platform_lock = ((void *)0);
	return 0;
}
```

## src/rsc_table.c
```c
/*
 * Copyright (c) 2014, Mentor Graphics Corporation
 * All rights reserved.
 * Copyright (c) 2015 Xilinx, Inc. All rights reserved.
 * Copyright 2020 NXP.
 * Copyright (c) 2022 Laird Connectivity
 * All rights reserved.
 *
 * SPDX-License-Identifier: BSD-3-Clause
 */

/* This file populates resource table for BM remote
 * for use by the Linux Master */

#include "rsc_table.h"
#include "rpmsg_lite.h"
#include <string.h>

#define NUM_VRINGS 0x02

/* Place resource table in special ELF section */
#if defined(__ARMCC_VERSION) || defined(__GNUC__)
__attribute__((section(".resource_table")))
#elif defined(__ICCARM__)
#pragma location = ".resource_table"
#else
#error Compiler not supported!
#endif

const struct remote_resource_table resources = {
	/* Version */
	1,

	/* NUmber of table entries */
	NO_RESOURCE_ENTRIES,
	/* reserved fields */
	{
		0,
		0,
	},

	/* Offsets of rsc entries */
	{
		offsetof(struct remote_resource_table, user_vdev),
	},

	/* SRTM virtio device entry */
	{
		RSC_VDEV,
		7,
		0,
		RSC_VDEV_FEATURE_NS,
		0,
		0,
		0,
		NUM_VRINGS,
		{ 0, 0 },
	},

	/* Vring rsc entry - part of vdev rsc entry */
	{ VDEV0_VRING_BASE, VRING_ALIGN, RL_BUFFER_COUNT, 0, 0 },
	{ VDEV0_VRING_BASE + VRING_SIZE, VRING_ALIGN, RL_BUFFER_COUNT, 1, 0 },
};

void copy_resource_table(void)
{
	/*
	* Resource table should be copied to VDEV0_VRING_BASE + RESOURCE_TABLE_OFFSET.
	* VDEV0_VRING_BASE is temperorily kept for backward compatibility, will be removed in future
	* release
	*/
	memcpy((void *)VDEV0_VRING_BASE, &resources, sizeof(resources));
	memcpy((void *)(VDEV0_VRING_BASE + RESOURCE_TABLE_OFFSET), &resources, sizeof(resources));
}
```
